AUTOSAR XML (schema 4-1-3)
standard types defined: boolean, uint16, uint8
package /UAES/ASW/CompuMethods
  compu method CM_boolean: 0=FALSE, 1=TRUE
package /UAES/ASW/DataConstrs
  range DC_boolean: raw 0..1
  range DC_uint16: raw 0..65535
  range DC_uint8: raw 0..255
package /UAES/ASW/DataTypeMappingSets
  data type mapping set DTMS_Door_DD
package /UAES/ASW/PortInterfaces
  client server interface IoHwAb_IoSigDio
    operation Di_Get: possible-error=E_NOT_OK
      arg id_u16: type=uint16, direction=IN, server-argument-impl-policy=USE-ARGUMENT-TYPE
      arg val_u8: type=uint8, direction=OUT, server-argument-impl-policy=USE-ARGUMENT-TYPE
    operation Do_Set: possible-error=E_NOT_OK
      arg id_u16: type=uint16, direction=IN, server-argument-impl-policy=USE-ARGUMENT-TYPE
      arg val_u8: type=uint8, direction=IN, server-argument-impl-policy=USE-ARGUMENT-TYPE
    error E_NOT_OK: error-code=1
  8 x sender receiver interface:
    gDoor_bChrgCapAjarSt: invalidation-policy{data-element=gDoor_bChrgCapAjarSt/Val, handle-invalid=DONT-INVALIDATE}
      data Val: sw-calibration-access=READ-ONLY, type=boolean
    gDoor_bFLDoorAjarSt: invalidation-policy{data-element=gDoor_bFLDoorAjarSt/Val, handle-invalid=DONT-INVALIDATE}
      data Val: sw-calibration-access=READ-ONLY, type=boolean
    gDoor_bFRDoorAjarSt: invalidation-policy{data-element=gDoor_bFRDoorAjarSt/Val, handle-invalid=DONT-INVALIDATE}
      data Val: sw-calibration-access=READ-ONLY, type=boolean
    gDoor_bFuelFlapAjarSt: invalidation-policy{data-element=gDoor_bFuelFlapAjarSt/Val, handle-invalid=DONT-INVALIDATE}
      data Val: sw-calibration-access=READ-ONLY, type=boolean
    gDoor_bHoodAjarSt: invalidation-policy{data-element=gDoor_bHoodAjarSt/Val, handle-invalid=DONT-INVALIDATE}
      data Val: sw-calibration-access=READ-ONLY, type=boolean
    gDoor_bRLDoorAjarSt: invalidation-policy{data-element=gDoor_bRLDoorAjarSt/Val, handle-invalid=DONT-INVALIDATE}
      data Val: sw-calibration-access=READ-ONLY, type=boolean
    gDoor_bRRDoorAjarSt: invalidation-policy{data-element=gDoor_bRRDoorAjarSt/Val, handle-invalid=DONT-INVALIDATE}
      data Val: sw-calibration-access=READ-ONLY, type=boolean
    gDoor_bTrunkAjarSt: invalidation-policy{data-element=gDoor_bTrunkAjarSt/Val, handle-invalid=DONT-INVALIDATE}
      data Val: sw-calibration-access=READ-ONLY, type=boolean
package /UAES/ASW/SwComponentTypes
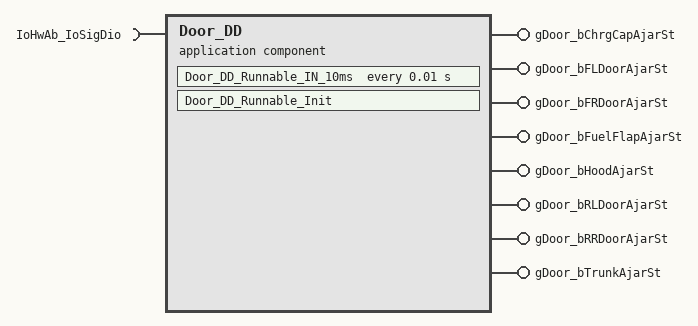
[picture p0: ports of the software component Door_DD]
  application sw component type Door_DD
    8 x provide port:
      gDoor_bChrgCapAjarSt: nonqueued-sender-com-spec{data-element=gDoor_bChrgCapAjarSt/Val, init-value=0}, provided-interface=gDoor_bChrgCapAjarSt
      gDoor_bFLDoorAjarSt: nonqueued-sender-com-spec{data-element=gDoor_bFLDoorAjarSt/Val, init-value=0}, provided-interface=gDoor_bFLDoorAjarSt
      gDoor_bFRDoorAjarSt: nonqueued-sender-com-spec{data-element=gDoor_bFRDoorAjarSt/Val, init-value=0}, provided-interface=gDoor_bFRDoorAjarSt
      gDoor_bFuelFlapAjarSt: nonqueued-sender-com-spec{data-element=gDoor_bFuelFlapAjarSt/Val, init-value=0}, provided-interface=gDoor_bFuelFlapAjarSt
      gDoor_bHoodAjarSt: nonqueued-sender-com-spec{data-element=gDoor_bHoodAjarSt/Val, init-value=0}, provided-interface=gDoor_bHoodAjarSt
      gDoor_bRLDoorAjarSt: nonqueued-sender-com-spec{data-element=gDoor_bRLDoorAjarSt/Val, init-value=0}, provided-interface=gDoor_bRLDoorAjarSt
      gDoor_bRRDoorAjarSt: nonqueued-sender-com-spec{data-element=gDoor_bRRDoorAjarSt/Val, init-value=0}, provided-interface=gDoor_bRRDoorAjarSt
      gDoor_bTrunkAjarSt: nonqueued-sender-com-spec{data-element=gDoor_bTrunkAjarSt/Val, init-value=0}, provided-interface=gDoor_bTrunkAjarSt
    require port IoHwAb_IoSigDio: required-com-specs=[Di_Get, Do_Set], required-interface=IoHwAb_IoSigDio
    behavior Door_DD_InternalBehavior: data-type-mapping=DTMS_Door_DD
      timing event TMT_Door_DD_Runnable_IN_10ms: start-on-event=Door_DD_Runnable_IN_10ms, period=0.01
      init event Door_DD_InitEvent: start-on-event=Door_DD_Runnable_Init
      runnable Door_DD_Runnable_IN_10ms
        data-send-points:
          8 x access:
            SEND_gDoor_bChrgCapAjarSt_Val: accessed-variable=gDoor_bChrgCapAjarSt.Val
            SEND_gDoor_bFLDoorAjarSt_Val: accessed-variable=gDoor_bFLDoorAjarSt.Val
            SEND_gDoor_bFRDoorAjarSt_Val: accessed-variable=gDoor_bFRDoorAjarSt.Val
            SEND_gDoor_bFuelFlapAjarSt_Val: accessed-variable=gDoor_bFuelFlapAjarSt.Val
            SEND_gDoor_bHoodAjarSt_Val: accessed-variable=gDoor_bHoodAjarSt.Val
            SEND_gDoor_bRLDoorAjarSt_Val: accessed-variable=gDoor_bRLDoorAjarSt.Val
            SEND_gDoor_bRRDoorAjarSt_Val: accessed-variable=gDoor_bRRDoorAjarSt.Val
            SEND_gDoor_bTrunkAjarSt_Val: accessed-variable=gDoor_bTrunkAjarSt.Val
        sync call SC_IoHwAb_IoSigDio_Di_Get: operation=IoHwAb_IoSigDio.Di_Get, timeout=0
      runnable Door_DD_Runnable_Init
  swc implementation Door_DD_imp: behavior=Door_DD_InternalBehavior
    code-descriptors:
      code Default: artifact-descriptors=autosar-engineering-object={short-label=Default, category=SWSRC}
package /UAES/ASW/Units
  unit NoUnit: factor-si-to-unit=1, offset-si-to-unit=0
